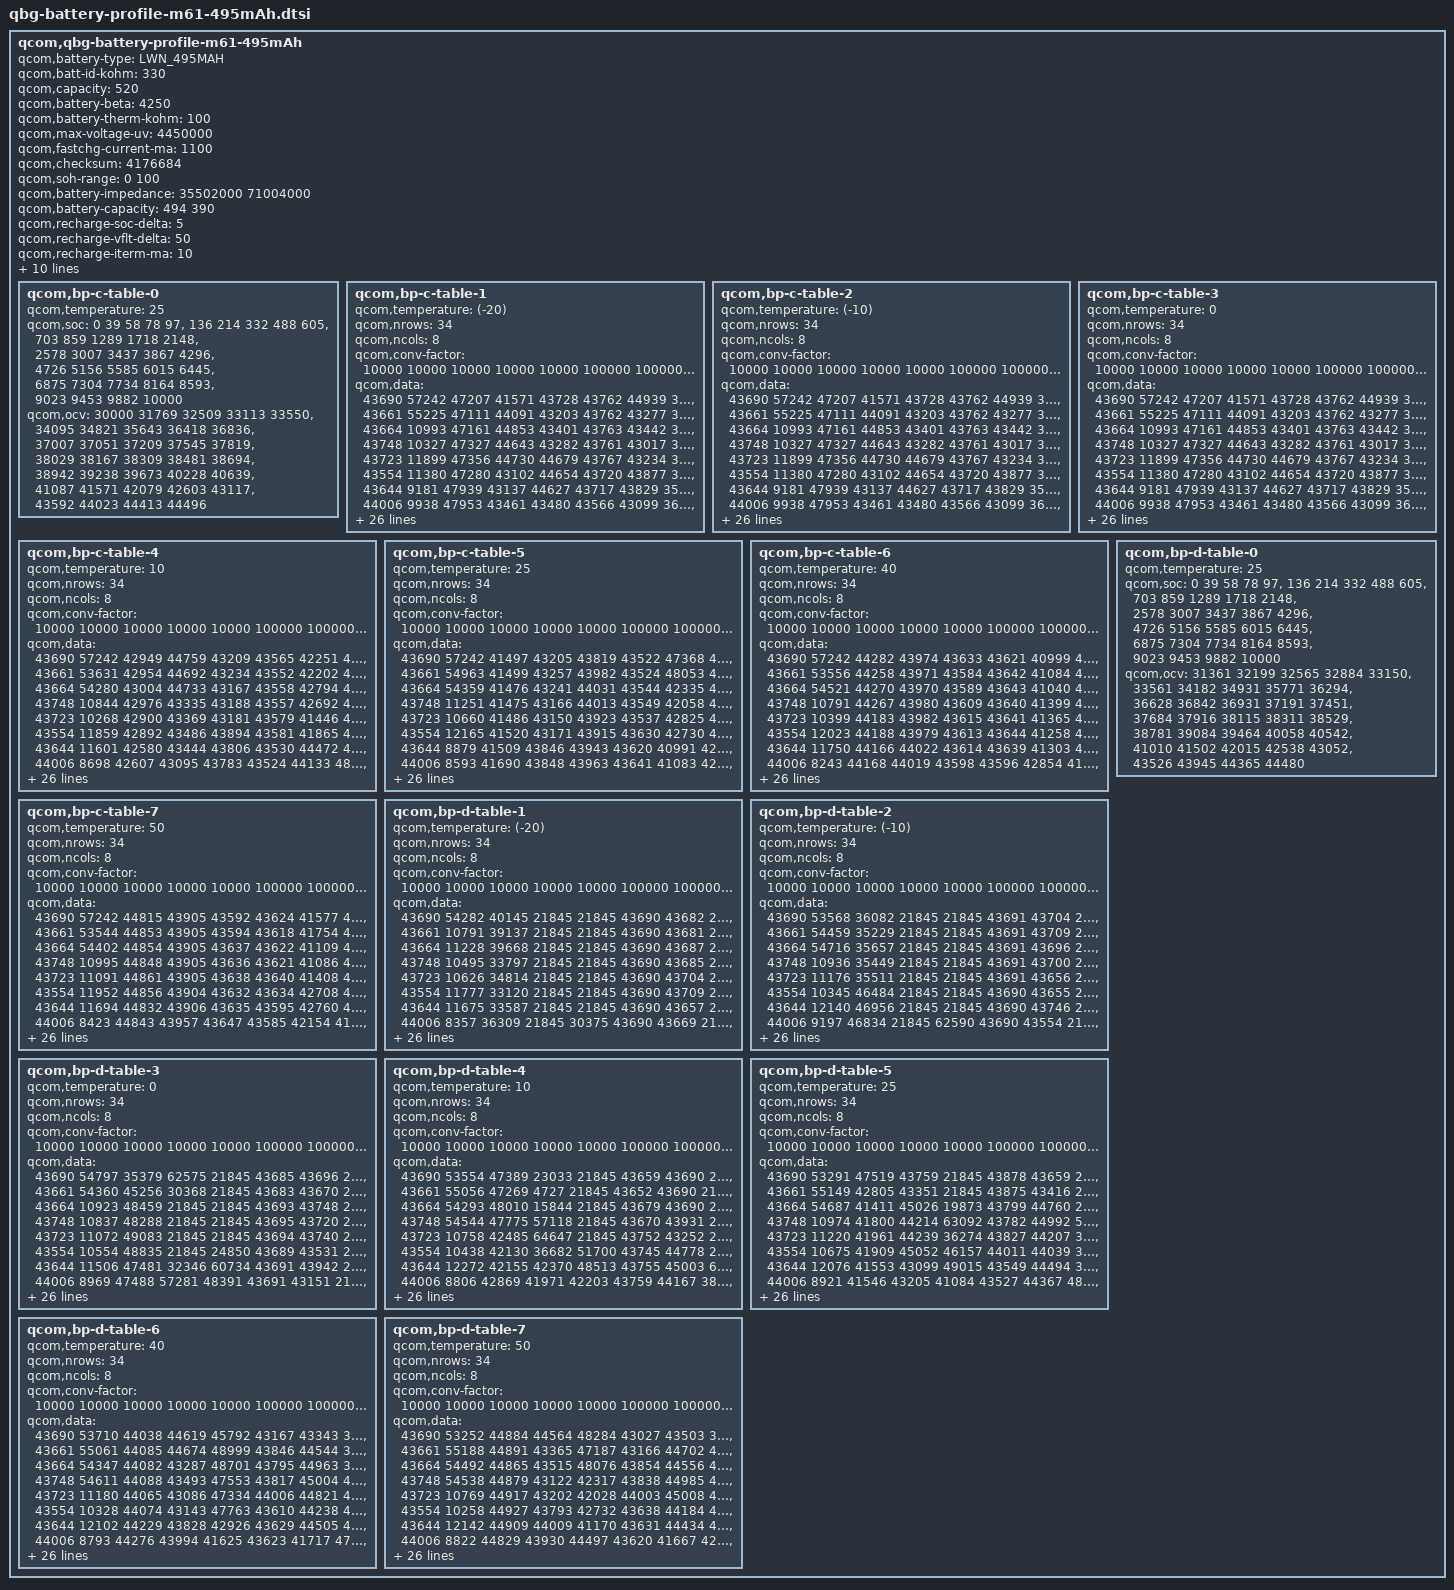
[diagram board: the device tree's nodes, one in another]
qcom,qbg-battery-profile-m61-495mAh {
	qcom,battery-type = "LWN_495MAH";
	qcom,batt-id-kohm = <330>;
	qcom,capacity = <520>;
	qcom,battery-beta = <4250>;
	qcom,battery-therm-kohm = <100>;
	qcom,max-voltage-uv = <4450000>;
	qcom,fastchg-current-ma = <1100>;
	qcom,checksum = <4176684>; /*@5, 0.005V, 4% */
	qcom,soh-range = <0 100>;
	/* Nominal_Impedance in 10nohm @ SOC 50% 25C* 0:fresh cell, 1: aged cell */
	qcom,battery-impedance = <35502000 71004000>;
	/* Nominal_Capacity in mAh. 0: fresh cell, 1:aged cell */
	qcom,battery-capacity = <494 390>; 
	/* SOC delta (in percent) dropped from EOC SOC to enable recharge */
	qcom,recharge-soc-delta =<5>; 
	/* vfloat delta (in mV) dropped from regular vfloat in recharge */
	qcom,recharge-vflt-delta =<50>;
	/* Termination current (in mA) in recharge */
	qcom,recharge-iterm-ma = <10>;

	qcom,jeita-fcc-ranges = <20 170 227500
				171 430 1100000
				431 450 227500>;

	qcom,jeita-fv-ranges = <20 170 4420000
				171 430 4420000
				431 450 4420000>;

	/* COOL = 17 DegC, WARM = 43.1 DegC */
	qcom,jeita-soft-thresholds = <0x263b 0x13a4>;
	/* COLD = 2 DegC, HOT = 45 DegC */
	qcom,jeita-hard-thresholds = <0x3117 0x1290>;
	/* COOL = 17.1 DegC, WARM = 43 DegC*/
	qcom,jeita-soft-hys-thresholds = <0x2627 0x1382>;
	qcom,step-jeita-hysteresis = <5 5>;
	qcom,jeita-soft-fcc-ua = <227500 227500>;
	qcom,jeita-soft-fv-uv = <4420000 4420000>;

	qcom,bp-c-table-0 {
		qcom,temperature = <25>;
		qcom,soc = <    0    39    58    78    97>,
			<  136   214   332   488   605>,
			<  703   859  1289  1718  2148>,
			< 2578  3007  3437  3867  4296>,
			< 4726  5156  5585  6015  6445>,
			< 6875  7304  7734  8164  8593>,
			< 9023  9453  9882 10000>;
		qcom,ocv = <30000 31769 32509 33113 33550>,
			<34095 34821 35643 36418 36836>,
			<37007 37051 37209 37545 37819>,
			<38029 38167 38309 38481 38694>,
			<38942 39238 39673 40228 40639>,
			<41087 41571 42079 42603 43117>,
			<43592 44023 44413 44496>;
	};
	qcom,bp-c-table-1 {
		qcom,temperature = <(-20)>;
		qcom,nrows = <34>;
		qcom,ncols = <8>;
		qcom,conv-factor = <10000 10000 10000 10000 10000 100000 100000 10000>;
		qcom,data = <43690 57242 47207 41571 43728 43762 44939 34481>,
			<43661 55225 47111 44091 43203 43762 43277 32881>,
			<43664 10993 47161 44853 43401 43763 43442 32924>,
			<43748 10327 47327 44643 43282 43761 43017 33595>,
			<43723 11899 47356 44730 44679 43767 43234 33370>,
			<43554 11380 47280 43102 44654 43720 43877 36195>,
			<43644  9181 47939 43137 44627 43717 43829 35988>,
			<44006  9938 47953 43461 43480 43566 43099 36841>,
			<43842  9720 47937 44695 43226 43570 44070 36566>,
			<43255 14852 47920 43982 44568 43569 44029 35228>,
			<43029 14917 48117 43105 43308 43571 43241 35209>,
			<43505 15295 47996 44597 43138 43528 41627 35315>,
			<44963 15186 47928 44999 43402 43533 41365 36550>,
			<44060 14833 48085 44817 43380 43523 42708 36592>,
			<41678 16069 48118 44877 44747 43527 42938 36560>,
			<41144 16278 48091 44165 44765 43520 42565 36585>,
			<41237 16181 48058 44224 44649 43523 42933 36590>,
			<42951 15537 48061 44080 44652 43522 42593 36528>,
			<42417 15378 47682 44056 44663 43532 41423 35190>,
			<47714 15826 47731 44045 45025 43535 41876 36525>,
			<47324 13036 47735 44080 44086 43535 41563 36776>,
			<48782 13302 47691 44032 44442 43532 41429 36829>,
			<49019 12684 47741 44148 45003 43522 42288 35082>,
			<48597 14234 47625 44227 43278 43529 41212 35808>,
			<45959 13424 48046 44089 43290 43531 41745 35632>,
			<45169  2610 47642 44060 43340 43572 41584 34959>,
			<46626  2260 47655 44429 43288 43543 41593 34857>,
			<46236  3806 47674 44542 43359 43537 41681 35219>,
			<46414  3288 47719 44494 44993 43575 44455 36819>,
			<35643   723 48073 44317 44402 43574 44859 32903>,
			<35221   194 47930 44419 41321 43535 43345 39568>,
			<36423  1765 47934 43070 42133 43211 44022 39804>,
			<35888  1835 41458 43557 47821 43911 43542 39079>,
			<36282  1811 41645 43767 47709 43750 43545 39804>;
	};
	qcom,bp-c-table-2 {
		qcom,temperature = <(-10)>;
		qcom,nrows = <34>;
		qcom,ncols = <8>;
		qcom,conv-factor = <10000 10000 10000 10000 10000 100000 100000 10000>;
		qcom,data = <43690 57242 47207 41571 43728 43762 44939 34481>,
			<43661 55225 47111 44091 43203 43762 43277 32881>,
			<43664 10993 47161 44853 43401 43763 43442 32924>,
			<43748 10327 47327 44643 43282 43761 43017 33595>,
			<43723 11899 47356 44730 44679 43767 43234 33370>,
			<43554 11380 47280 43102 44654 43720 43877 36195>,
			<43644  9181 47939 43137 44627 43717 43829 35988>,
			<44006  9938 47953 43461 43480 43566 43099 36841>,
			<43842  9720 47937 44695 43226 43570 44070 36566>,
			<43255 14852 47920 43982 44568 43569 44029 35228>,
			<43029 14917 48117 43105 43308 43571 43241 35209>,
			<43505 15295 47996 44597 43138 43528 41627 35315>,
			<44963 15186 47928 44999 43402 43533 41365 36550>,
			<44060 14833 48085 44817 43380 43523 42708 36592>,
			<41678 16069 48118 44877 44747 43527 42938 36560>,
			<41144 16278 48091 44165 44765 43520 42565 36585>,
			<41237 16181 48058 44224 44649 43523 42933 36590>,
			<42951 15537 48061 44080 44652 43522 42593 36528>,
			<42417 15378 47682 44056 44663 43532 41423 35190>,
			<47714 15826 47731 44045 45025 43535 41876 36525>,
			<47324 13036 47735 44080 44086 43535 41563 36776>,
			<48782 13302 47691 44032 44442 43532 41429 36829>,
			<49019 12684 47741 44148 45003 43522 42288 35082>,
			<48597 14234 47625 44227 43278 43529 41212 35808>,
			<45959 13424 48046 44089 43290 43531 41745 35632>,
			<45169  2610 47642 44060 43340 43572 41584 34959>,
			<46626  2260 47655 44429 43288 43543 41593 34857>,
			<46236  3806 47674 44542 43359 43537 41681 35219>,
			<46414  3288 47719 44494 44993 43575 44455 36819>,
			<35643   723 48073 44317 44402 43574 44859 32903>,
			<35221   194 47930 44419 41321 43535 43345 39568>,
			<36423  1765 47934 43070 42133 43211 44022 39804>,
			<35888  1835 41458 43557 47821 43911 43542 39079>,
			<36282  1811 41645 43767 47709 43750 43545 39804>;
	};
	qcom,bp-c-table-3 {
		qcom,temperature = <0>;
		qcom,nrows = <34>;
		qcom,ncols = <8>;
		qcom,conv-factor = <10000 10000 10000 10000 10000 100000 100000 10000>;
		qcom,data = <43690 57242 47207 41571 43728 43762 44939 34481>,
			<43661 55225 47111 44091 43203 43762 43277 32881>,
			<43664 10993 47161 44853 43401 43763 43442 32924>,
			<43748 10327 47327 44643 43282 43761 43017 33595>,
			<43723 11899 47356 44730 44679 43767 43234 33370>,
			<43554 11380 47280 43102 44654 43720 43877 36195>,
			<43644  9181 47939 43137 44627 43717 43829 35988>,
			<44006  9938 47953 43461 43480 43566 43099 36841>,
			<43842  9720 47937 44695 43226 43570 44070 36566>,
			<43255 14852 47920 43982 44568 43569 44029 35228>,
			<43029 14917 48117 43105 43308 43571 43241 35209>,
			<43505 15295 47996 44597 43138 43528 41627 35315>,
			<44963 15186 47928 44999 43402 43533 41365 36550>,
			<44060 14833 48085 44817 43380 43523 42708 36592>,
			<41678 16069 48118 44877 44747 43527 42938 36560>,
			<41144 16278 48091 44165 44765 43520 42565 36585>,
			<41237 16181 48058 44224 44649 43523 42933 36590>,
			<42951 15537 48061 44080 44652 43522 42593 36528>,
			<42417 15378 47682 44056 44663 43532 41423 35190>,
			<47714 15826 47731 44045 45025 43535 41876 36525>,
			<47324 13036 47735 44080 44086 43535 41563 36776>,
			<48782 13302 47691 44032 44442 43532 41429 36829>,
			<49019 12684 47741 44148 45003 43522 42288 35082>,
			<48597 14234 47625 44227 43278 43529 41212 35808>,
			<45959 13424 48046 44089 43290 43531 41745 35632>,
			<45169  2610 47642 44060 43340 43572 41584 34959>,
			<46626  2260 47655 44429 43288 43543 41593 34857>,
			<46236  3806 47674 44542 43359 43537 41681 35219>,
			<46414  3288 47719 44494 44993 43575 44455 36819>,
			<35643   723 48073 44317 44402 43574 44859 32903>,
			<35221   194 47930 44419 41321 43535 43345 39568>,
			<36423  1765 47934 43070 42133 43211 44022 39804>,
			<35888  1835 41458 43557 47821 43911 43542 39079>,
			<36282  1811 41645 43767 47709 43750 43545 39804>;
	};
	qcom,bp-c-table-4 {
		qcom,temperature = <10>;
		qcom,nrows = <34>;
		qcom,ncols = <8>;
		qcom,conv-factor = <10000 10000 10000 10000 10000 100000 100000 10000>;
		qcom,data = <43690 57242 42949 44759 43209 43565 42251 45356>,
			<43661 53631 42954 44692 43234 43552 42202 45107>,
			<43664 54280 43004 44733 43167 43558 42794 45244>,
			<43748 10844 42976 43335 43188 43557 42692 45882>,
			<43723 10268 42900 43369 43181 43579 41446 45985>,
			<43554 11859 42892 43486 43894 43581 41865 45757>,
			<43644 11601 42580 43444 43806 43530 44472 48216>,
			<44006  8698 42607 43095 43783 43524 44133 48359>,
			<43842  9414 42498 43099 43784 43551 44496 49006>,
			<43255 15032 42496 43084 43837 43624 44402 49113>,
			<43029 14854 42554 43426 44003 43542 41055 49087>,
			<43505 14964 42697 43438 43814 43536 41557 49074>,
			<44963 15164 42654 43310 43226 43625 41045 48967>,
			<44060 14424 42649 43281 43438 43628 42531 48365>,
			<41678 16058 42624 43382 43487 43629 42924 48169>,
			<41144 15985 42686 44729 43270 43631 42828 48141>,
			<41237 16356 41292 44680 43281 43624 42997 48162>,
			<42951 16252 41236 44685 43302 43543 42668 48295>,
			<42417 15583 41230 44774 43322 43537 41249 48288>,
			<47714 15762 41222 44759 43267 43549 41168 48269>,
			<47324 12940 41228 44554 44709 43536 41667 48188>,
			<48782 13290 41249 44586 45054 43542 44500 48430>,
			<49019 12413 41433 44724 44809 43537 41657 48630>,
			<48597 14210 41439 44707 43104 43539 41920 48883>,
			<45959 13420 41439 44726 43104 43539 41910 48884>,
			<45169  2607 41464 44698 43083 43549 41673 48674>,
			<46626  2249 41434 44768 43449 43538 44376 48730>,
			<46236  3828 41278 44764 43488 43539 44379 48936>,
			<46414  3265 41242 44607 43325 43539 44293 48286>,
			<35643   735 41337 44653 44768 43549 44121 48425>,
			<35221   243 42668 44628 44225 43549 44905 45084>,
			<36423  1709 42682 44589 41837 43541 44685 46136>,
			<35888  1831 41357 43209 41671 43629 43785 45462>,
			<36282  1897 43961 43566 42594 43935 43588 48938>;
	};
	qcom,bp-c-table-5 {
		qcom,temperature = <25>;
		qcom,nrows = <34>;
		qcom,ncols = <8>;
		qcom,conv-factor = <10000 10000 10000 10000 10000 100000 100000 10000>;
		qcom,data = <43690 57242 41497 43205 43819 43522 47368 42116>,
			<43661 54963 41499 43257 43982 43524 48053 42828>,
			<43664 54359 41476 43241 44031 43544 42335 42768>,
			<43748 11251 41475 43166 44013 43549 42058 42784>,
			<43723 10660 41486 43150 43923 43537 42825 42992>,
			<43554 12165 41520 43171 43915 43630 42730 42923>,
			<43644  8879 41509 43846 43943 43620 40991 42511>,
			<44006  8593 41690 43848 43963 43641 41083 42713>,
			<43842  9448 41720 43896 43961 43594 41189 42645>,
			<43255  9550 41721 43875 43936 43592 40972 42686>,
			<43029 14885 41620 43776 43613 43599 41074 41331>,
			<43505 14865 41630 43799 43966 43594 40961 41309>,
			<44963 15347 41653 43863 43901 43592 41853 42615>,
			<44060 14339 41636 43170 43185 43638 41045 42915>,
			<41678 14609 44382 43151 43215 43639 41325 42992>,
			<41144 15911 44361 43156 43224 43638 42681 42945>,
			<41237 16317 44388 43246 43261 43635 42496 42904>,
			<42951 16143 44318 43152 43161 43642 41092 42562>,
			<42417 15611 44297 43257 43154 43623 41930 42591>,
			<47714 15756 44347 43207 43257 43619 41646 42931>,
			<47324 12980 44330 43022 43065 43617 44540 42794>,
			<48782 13292 44504 43014 43397 43642 44182 42166>,
			<49019 12371 44495 43206 43431 43642 44267 42782>,
			<48597 14222 44529 43144 43799 43617 41615 41308>,
			<45959 13333 44541 43144 43781 43620 44307 41289>,
			<45169  2773 44538 43136 43884 43642 44428 41301>,
			<46626  2249 44537 43143 43865 43642 44229 42649>,
			<46236  3829 44533 43239 43146 43642 44060 42534>,
			<46414  3265 44481 43214 43249 43620 44079 42586>,
			<35643   711 44503 43220 43021 43642 44066 42944>,
			<35221   226 44336 43061 43413 43646 44246 42226>,
			<36423   349 44289 43067 44646 43643 44652 42364>,
			<35888  2007 44424 43840 44915 43621 43091 47782>,
			<36282  1914 43680 43926 41722 43999 43897 41494>;
	};
	qcom,bp-c-table-6 {
		qcom,temperature = <40>;
		qcom,nrows = <34>;
		qcom,ncols = <8>;
		qcom,conv-factor = <10000 10000 10000 10000 10000 100000 100000 10000>;
		qcom,data = <43690 57242 44282 43974 43633 43621 40999 41983>,
			<43661 53556 44258 43971 43584 43642 41084 41957>,
			<43664 54521 44270 43970 43589 43643 41040 41953>,
			<43748 10791 44267 43980 43609 43640 41399 41964>,
			<43723 10399 44183 43982 43615 43641 41365 41963>,
			<43554 12023 44188 43979 43613 43644 41258 41887>,
			<43644 11750 44166 44022 43614 43639 41303 41906>,
			<44006  8243 44168 44019 43598 43596 42854 41566>,
			<43842 10008 44222 44005 43639 43610 42874 41592>,
			<43255  9676 44219 44001 43633 43602 42191 41579>,
			<43029 15084 44196 43931 43537 43950 47640 41515>,
			<43505 14888 44204 43906 43644 43604 42700 41530>,
			<44963 15265 44200 44022 43995 43947 41096 41972>,
			<44060 14565 44883 44030 43820 43604 41022 41975>,
			<41678 14796 44890 44026 43788 43607 41763 41950>,
			<41144 16108 44878 44027 43789 43603 41932 41946>,
			<41237 15954 44914 44007 43989 43614 41123 41885>,
			<42951 16166 44897 43976 43988 43588 41924 41961>,
			<42417 15598 44821 43988 43835 43596 41519 41927>,
			<47714 15793 44829 43825 43805 43592 44345 41732>,
			<47324 12978 44804 43781 43847 43595 44256 41821>,
			<48782 13293 44813 43874 43188 43637 44223 41108>,
			<49019 12712 44810 43825 43892 43599 44066 41839>,
			<48597 14264 44849 43920 43934 43611 44497 41473>,
			<45959 13338 44861 44013 43918 43589 44372 41482>,
			<45169  2782 44850 44025 44010 43615 44488 41569>,
			<46626  2290 44848 43998 44021 43610 41611 41895>,
			<46236  3839 44855 43989 43815 43585 44304 41953>,
			<46414  3274 44808 43823 43881 43588 44449 41767>,
			<35643   753 44801 43825 43869 43591 44518 41800>,
			<35221   152 44818 43781 43140 43584 44511 41105>,
			<36423   369 44906 43777 43126 43586 44254 41024>,
			<35888  1987 45018 43831 43270 43612 44933 41469>,
			<36282  1892 43404 43644 41701 43926 43044 41281>;
	};
	qcom,bp-c-table-7 {
		qcom,temperature = <50>;
		qcom,nrows = <34>;
		qcom,ncols = <8>;
		qcom,conv-factor = <10000 10000 10000 10000 10000 100000 100000 10000>;
		qcom,data = <43690 57242 44815 43905 43592 43624 41577 41675>,
			<43661 53544 44853 43905 43594 43618 41754 41727>,
			<43664 54402 44854 43905 43637 43622 41109 41722>,
			<43748 10995 44848 43905 43636 43621 41086 41697>,
			<43723 11091 44861 43905 43638 43640 41408 41711>,
			<43554 11952 44856 43904 43632 43634 42708 41617>,
			<43644 11694 44832 43906 43635 43595 42760 41602>,
			<44006  8423 44843 43957 43647 43585 42154 41632>,
			<43842 10184 45008 43955 43645 43610 42030 44368>,
			<43255  9661 45022 43962 43620 43600 42097 44404>,
			<43029 15017 45016 43602 43525 43967 47896 44342>,
			<43505 15072 44997 43611 43539 43942 42580 44298>,
			<44963 14946 44998 43916 44028 43948 41052 41692>,
			<44060 14496 44995 43915 44030 43943 41331 41667>,
			<41678 14733 45000 43959 43982 43943 41206 41671>,
			<41144 16062 45040 43966 43976 43941 41737 41717>,
			<41237 15946 45048 43943 43925 43936 41186 41604>,
			<42951 16171 45026 43911 43927 43947 41003 41699>,
			<42417 15509 45032 43925 44016 43614 41544 41682>,
			<47714 15798 44950 44031 43986 43588 44388 41477>,
			<47324 12980 44957 43996 43835 43584 44420 41538>,
			<48782 13309 44955 43997 43804 43597 44278 41891>,
			<49019 12733 44935 43920 43819 43615 44070 41531>,
			<48597 14259 44930 43603 43945 43939 41700 44398>,
			<45959 13330 44937 43937 43600 43945 41880 44393>,
			<45169  2773 44942 43959 43964 43607 41568 44382>,
			<46626  2253 44943 43917 44011 43602 41682 41600>,
			<46236  3790 44940 44014 43978 43613 41888 41666>,
			<46414  3265 44930 44005 43823 43613 41527 41525>,
			<35643   718 44932 44028 43781 43612 41653 41599>,
			<35221   158 44957 43980 43901 43602 41631 41912>,
			<36423   381 44946 43973 43239 43606 44356 41788>,
			<35888  1985 44633 43909 43022 43943 44847 41920>,
			<36282  1913 43680 43574 41530 43940 43813 44570>;
	};
	qcom,bp-d-table-0 {
		qcom,temperature = <25>;
		qcom,soc = <    0    39    58    78    97>,
			<  136   214   332   488   605>,
			<  703   859  1289  1718  2148>,
			< 2578  3007  3437  3867  4296>,
			< 4726  5156  5585  6015  6445>,
			< 6875  7304  7734  8164  8593>,
			< 9023  9453  9882 10000>;
		qcom,ocv = <31361 32199 32565 32884 33150>,
			<33561 34182 34931 35771 36294>,
			<36628 36842 36931 37191 37451>,
			<37684 37916 38115 38311 38529>,
			<38781 39084 39464 40058 40542>,
			<41010 41502 42015 42538 43052>,
			<43526 43945 44365 44480>;
	};
	qcom,bp-d-table-1 {
		qcom,temperature = <(-20)>;
		qcom,nrows = <34>;
		qcom,ncols = <8>;
		qcom,conv-factor = <10000 10000 10000 10000 10000 100000 100000 10000>;
		qcom,data = <43690 54282 40145 21845 21845 43690 43682 21845>,
			<43661 10791 39137 21845 21845 43690 43681 21845>,
			<43664 11228 39668 21845 21845 43690 43687 21845>,
			<43748 10495 33797 21845 21845 43690 43685 21845>,
			<43723 10626 34814 21845 21845 43690 43704 21845>,
			<43554 11777 33120 21845 21845 43690 43709 21845>,
			<43644 11675 33587 21845 21845 43690 43657 21845>,
			<44006  8357 36309 21845 30375 43690 43669 21845>,
			<43842  9776 36225 21845 50109 43690 43736 21845>,
			<43255 10103 36286 21845 60673 43690 43524 21845>,
			<43029  9253 36758 21845 37431 43690 43641 21845>,
			<43505  9701 36602 21845 33458 43690 43952 21845>,
			<44963 15054 35219 31702 47045 43691 43984 21845>,
			<44060 15244 34941 10134 48847 43691 43879 21845>,
			<41678 15218 35674 49203 47800 43688 43173 21845>,
			<41144 14394 35631 62601 42476 43688 43139 21845>,
			<41237 14743 35071 63648 42064 43688 43190 23630>,
			<42951 14666 35449 58363 42019 43688 43140 18089>,
			<42417 16090 35755 60037 42144 43688 43197 19196>,
			<47714 15957 35759 37508 42772 43688 43863 31818>,
			<47324 16189 35394 39507 42778 43688 43843 25780>,
			<48782 15609 35404 33061 42768 43688 43866 28128>,
			<49019 15839 35329 33570 42209 43688 43092 28554>,
			<48597 13261 35838 33552 49047 43688 45001 25445>,
			<45959 12701 35719 33383 45525 43688 44746 25759>,
			<45169 14285 35808 32964 34890 43689 44793 31793>,
			<46626 13604 35723 34349 33715 43689 43386 29855>,
			<46236  2849 35440 34176 33125 43689 43447 18745>,
			<46414  2338 35449 39310 34745 43689 43129 17320>,
			<35643  3847 35741 40280 34208 43694 43021 23533>,
			<35221  3399 35834 38493 39340 43694 43137 22222>,
			<36423   203 35615 58051 34004 43689 43879 21845>,
			<35888  1930 34969 64851 34912 43689 43820 21845>,
			<36282  1863 34966 63156 46139 43689 43986 21845>;
	};
	qcom,bp-d-table-2 {
		qcom,temperature = <(-10)>;
		qcom,nrows = <34>;
		qcom,ncols = <8>;
		qcom,conv-factor = <10000 10000 10000 10000 10000 100000 100000 10000>;
		qcom,data = <43690 53568 36082 21845 21845 43691 43704 21845>,
			<43661 54459 35229 21845 21845 43691 43709 21845>,
			<43664 54716 35657 21845 21845 43691 43696 21845>,
			<43748 10936 35449 21845 21845 43691 43700 21845>,
			<43723 11176 35511 21845 21845 43691 43656 21845>,
			<43554 10345 46484 21845 21845 43690 43655 21845>,
			<43644 12140 46956 21845 21845 43690 43746 21845>,
			<44006  9197 46834 21845 62590 43690 43554 21845>,
			<43842  9785 45538 21845 36347 43690 43946 21845>,
			<43255  9448 45268 18073 46792 43691 43874 21845>,
			<43029  9285 45123  6051 48217 43691 43850 21845>,
			<43505  9671 45161  9665 42356 43691 43172 21845>,
			<44963 14998 46037 52544 41337 43691 43212 24339>,
			<44060 15259 45983 63707 41219 43691 43071 29513>,
			<41678 14476 45942 37950 41300 43688 43112 27547>,
			<41144 14415 45928 33027 41468 43688 43106   752>,
			<41237 14638 46075 46327 40965 43689 43032 16268>,
			<42951 16034 45859 48971 41091 43689 43226 11308>,
			<42417 15918 46047 42352 41730 43694 43152 53354>,
			<47714 16292 46069 42685 41983 43695 43189 56038>,
			<47324 16223 46029 41277 41145 43683 43302 51108>,
			<48782 15813 45851 42891 42824 43700 44225 50426>,
			<49019 12877 45252 42554 47875 43749 45005 50258>,
			<48597 12304 46077 42963 49124 43553 45021 55531>,
			<45959 13904 46049 47857 45313 43582 44816 53432>,
			<45169 13723 46047 47313 35763 43578 44984 54637>,
			<46626  2956 45926 48693 35738 43560 44790 10390>,
			<46236  2470 45827 48381 46421 43736 44730 10504>,
			<46414  4028 46061 48390 46450 43715 44715 12052>,
			<35643  3481 45883 45990 35427 43726 44718  8982>,
			<35221   903 45865 45941 35349 43767 43481  9943>,
			<36423    88 46038 45209 46019 43757 43008  8417>,
			<35888  1950 45865 45294 42352 43651 43776 10684>,
			<36282  1858 45859 45202 42069 43656 43978 10943>;
	};
	qcom,bp-d-table-3 {
		qcom,temperature = <0>;
		qcom,nrows = <34>;
		qcom,ncols = <8>;
		qcom,conv-factor = <10000 10000 10000 10000 10000 100000 100000 10000>;
		qcom,data = <43690 54797 35379 62575 21845 43685 43696 21845>,
			<43661 54360 45256 30368 21845 43683 43670 21845>,
			<43664 10923 48459 21845 21845 43693 43748 21845>,
			<43748 10837 48288 21845 21845 43695 43720 21845>,
			<43723 11072 49083 21845 21845 43694 43740 21845>,
			<43554 10554 48835 21845 24850 43689 43531 21845>,
			<43644 11506 47481 32346 60734 43691 43942 21845>,
			<44006  8969 47488 57281 48391 43691 43151 21845>,
			<43842  9850 47193 40430 42604 43688 43117  1670>,
			<43255  9424 47117 36647 42509 43688 43037 15151>,
			<43029  9606 47132 45406 41244 43689 43014 10821>,
			<43505  9531 47159 47491 41969 43694 43008 50349>,
			<44963 15080 47263 41264 44503 43682 43424 64795>,
			<44060 15150 47284 44414 44470 43661 44628 58009>,
			<41678 14397 47342 44089 44338 43736 44452 38298>,
			<41144 14829 47244 44866 44041 43557 44465 40419>,
			<41237 14699 47252 45008 45037 43573 44132 39718>,
			<42951 16096 47277 45043 44639 43531 44477 33941>,
			<42417 16313 47295 45017 44263 43532 44444 33935>,
			<47714 15531 47328 44827 44524 43523 44103 34678>,
			<47324 15776 47342 44202 44313 43523 44050 34774>,
			<48782 13026 47941 44282 41518 43521 44063 34562>,
			<49019 13154 47294 44033 41130 43520 44274 33919>,
			<48597 12568 47269 44493 42763 43527 44219 39318>,
			<45959 13485 47988 41473 47423 43539 45003 37065>,
			<45169 13632 47992 41579 47178 43526 43359 37714>,
			<46626  2920 47893 41866 47665 43530 43293 37441>,
			<46236  2320 47995 41783 42476 43570 44730 37490>,
			<46414  3949 47954 41833 42394 43583 44755 37721>,
			<35643  3425 47963 41738 42314 43583 44591 38655>,
			<35221   774 47232 41942 42305 43580 44744 38778>,
			<36423   498 47326 41888 42549 43557 44786 38515>,
			<35888  2016 47201 41689 41705 43566 44742 37780>,
			<36282  1911 47224 41726 44403 43561 44753 40206>;
	};
	qcom,bp-d-table-4 {
		qcom,temperature = <10>;
		qcom,nrows = <34>;
		qcom,ncols = <8>;
		qcom,conv-factor = <10000 10000 10000 10000 10000 100000 100000 10000>;
		qcom,data = <43690 53554 47389 23033 21845 43659 43690 21845>,
			<43661 55056 47269  4727 21845 43652 43690 21845>,
			<43664 54293 48010 15844 21845 43679 43690 21845>,
			<43748 54544 47775 57118 21845 43670 43931 21845>,
			<43723 10758 42485 64647 21845 43752 43252 21845>,
			<43554 10438 42130 36682 51700 43745 44778 26294>,
			<43644 12272 42155 42370 48513 43755 45003 61447>,
			<44006  8806 42869 41971 42203 43759 44167 38264>,
			<43842  9865 42758 44073 41868 43769 44172 34187>,
			<43255  9396 42799 44913 44407 43742 44032 33620>,
			<43029  9626 42822 45040 44436 43740 44825 36275>,
			<43505  9569 42957 44753 44837 43736 44975 35016>,
			<44963 15074 42891 43378 43350 43555 44865 46879>,
			<44060 15308 42574 43503 43480 43572 45007 45294>,
			<41678 14529 42573 43394 43416 43547 44259 45624>,
			<41144 14747 42562 43511 43295 43550 41712 45603>,
			<41237 14661 42499 43509 44625 43626 44324 45964>,
			<42951 15874 42552 43322 44986 43631 44499 45651>,
			<42417 16322 42692 43275 44575 43630 44474 45750>,
			<47714 15599 42721 43276 44775 43624 44143 48577>,
			<47324 15846 42640 43281 44691 43627 44100 48537>,
			<48782 12843 42628 43367 44793 43541 44144 48565>,
			<49019 12456 42627 44711 45019 43543 44102 45775>,
			<48597 14005 42635 44648 41178 43624 44249 46266>,
			<45959 13470 42735 44671 41340 43626 44713 46444>,
			<45169  2748 42728 44614 41817 43549 43508 46257>,
			<46626  2900 42749 44938 44344 43526 43291 46840>,
			<46236  2388 42707 44958 44037 43522 44762 46754>,
			<46414  3234 42558 44981 44067 43522 44639 46846>,
			<35643   673 42616 44979 44158 43520 45017 47064>,
			<35221   835 42583 44639 44419 43525 44829 46136>,
			<36423   289 42920 44545 44071 43545 44902 46098>,
			<35888  2042 42582 44769 45033 43551 44829 46143>,
			<36282  1918 42578 44703 44617 43551 44809 46290>;
	};
	qcom,bp-d-table-5 {
		qcom,temperature = <25>;
		qcom,nrows = <34>;
		qcom,ncols = <8>;
		qcom,conv-factor = <10000 10000 10000 10000 10000 100000 100000 10000>;
		qcom,data = <43690 53291 47519 43759 21845 43878 43659 21845>,
			<43661 55149 42805 43351 21845 43875 43416 21845>,
			<43664 54687 41411 45026 19873 43799 44760 23945>,
			<43748 10974 41800 44214 63092 43782 44992 50578>,
			<43723 11220 41961 44239 36274 43827 44207 37859>,
			<43554 10675 41909 45052 46157 44011 44039 33799>,
			<43644 12076 41553 43099 49015 43549 44494 35130>,
			<44006  8921 41546 43205 41084 43527 44367 48403>,
			<43842  8465 41573 43163 44597 43624 41707 48041>,
			<43255 10092 41578 43151 43456 43631 41589 42274>,
			<43029  9662 41490 43144 43075 43622 41664 42075>,
			<43505  9536 41484 43146 43059 43645 44429 42046>,
			<44963 15081 41529 43850 43820 43634 41089 42915>,
			<44060 15341 41682 43872 43818 43636 41589 42514>,
			<41678 14561 41719 43885 43777 43594 41887 42512>,
			<41144 14750 41703 43842 43201 43599 41915 42962>,
			<41237 16054 41606 43181 43275 43595 44368 42037>,
			<42951 15945 41661 43183 43300 43595 44156 42194>,
			<42417 16141 41647 43168 43432 43636 44155 42864>,
			<47714 15403 44379 43183 43054 43635 44062 42899>,
			<47324 15831 44404 43842 43240 43644 44868 42598>,
			<48782 12806 44414 43864 43166 43621 44214 42512>,
			<49019 12418 44411 43138 43099 43640 44054 42756>,
			<48597 14032 44398 43108 41626 43639 44944 47413>,
			<45959 13556 44393 43109 44168 43643 43295 47927>,
			<45169  2712 44386 43021 44690 43625 43318 42272>,
			<46626  2228 44408 43043 43501 43540 44716 42022>,
			<46236  3765 44366 43203 43109 43626 44782 42838>,
			<46414  3200 44373 43153 43064 43624 44693 42776>,
			<35643   646 41661 43162 43224 43625 44670 42767>,
			<35221   172 41631 43137 43201 43616 44923 42858>,
			<36423   259 41675 43167 43216 43621 44417 42158>,
			<35888  2023 41534 43235 43060 43641 41698 42237>,
			<36282  1898 41483 43237 43014 43646 41615 42184>;
	};
	qcom,bp-d-table-6 {
		qcom,temperature = <40>;
		qcom,nrows = <34>;
		qcom,ncols = <8>;
		qcom,conv-factor = <10000 10000 10000 10000 10000 100000 100000 10000>;
		qcom,data = <43690 53710 44038 44619 45792 43167 43343 36825>,
			<43661 55061 44085 44674 48999 43846 44544 35711>,
			<43664 54347 44082 43287 48701 43795 44963 35514>,
			<43748 54611 44088 43493 47553 43817 45004 46320>,
			<43723 11180 44065 43086 47334 44006 44821 46611>,
			<43554 10328 44074 43143 47763 43610 44238 45927>,
			<43644 12102 44229 43828 42926 43629 44505 48996>,
			<44006  8793 44276 43994 41625 43623 41717 47642>,
			<43842  9891 44286 43981 43408 43638 41882 41273>,
			<43255 10078 44259 44019 43846 43593 41767 41092>,
			<43029  9600 44269 43980 43854 43584 41914 41101>,
			<43505  9586 44268 44016 43850 43588 44466 41138>,
			<44963 14989 44177 43919 43951 43602 41249 41552>,
			<44060 15256 44165 43905 44004 43951 41124 41874>,
			<41678 14493 44168 43911 43813 43605 41860 41946>,
			<41144 14780 44221 43953 43786 43951 44332 41935>,
			<41237 16007 44216 43927 43113 43967 44448 41015>,
			<42951 16298 44194 43933 43010 43942 44885 41171>,
			<42417 16149 44886 43909 43150 43945 44923 41800>,
			<47714 15420 44889 43907 43873 43605 44882 41949>,
			<47324 15675 44870 43917 43824 43600 44258 41952>,
			<48782 12817 44877 44014 43817 43613 44493 41952>,
			<49019 12440 44917 44003 43180 43610 44200 41854>,
			<48597 14032 44873 43889 44566 43595 44600 42886>,
			<45959 13549 44872 43877 43414 43647 44582 41216>,
			<45169  2746 44878 43788 43247 43646 44592 40992>,
			<46626  2909 44877 43827 43877 43646 44933 41133>,
			<46236  2399 44870 43833 43810 43645 44266 41750>,
			<46414  3927 44892 43985 43968 43595 44053 41766>,
			<35643  3412 44205 44021 43976 43586 44119 41944>,
			<35221   880 44217 44018 44022 43585 44377 41920>,
			<36423   296 44170 43926 43972 43608 44534 41932>,
			<35888  1949 44165 43967 43813 43600 44835 41929>,
			<36282  1819 44184 43942 43836 43606 44644 41928>;
	};
	qcom,bp-d-table-7 {
		qcom,temperature = <50>;
		qcom,nrows = <34>;
		qcom,ncols = <8>;
		qcom,conv-factor = <10000 10000 10000 10000 10000 100000 100000 10000>;
		qcom,data = <43690 53252 44884 44564 48284 43027 43503 35049>,
			<43661 55188 44891 43365 47187 43166 44702 46939>,
			<43664 54492 44865 43515 48076 43854 44556 45420>,
			<43748 54538 44879 43122 42317 43838 44985 45829>,
			<43723 10769 44917 43202 42028 44003 45008 48491>,
			<43554 10258 44927 43793 42732 43638 44184 48651>,
			<43644 12142 44909 44009 41170 43631 44434 47337>,
			<44006  8822 44829 43930 44497 43620 41667 42425>,
			<43842  8521 44802 43912 43097 43637 41910 41163>,
			<43255 10082 44802 43955 43800 43584 41746 41895>,
			<43029  9302 44812 43914 43900 43584 41645 41885>,
			<43505  9473 44808 43953 43845 43608 44139 41955>,
			<44963  9556 44852 43607 43950 43939 42167 41600>,
			<44060 15266 44863 43614 44002 43966 41820 41716>,
			<41678 14500 44838 43610 43998 43955 41708 41686>,
			<41144 14404 44844 43637 43997 43965 44097 41676>,
			<41237 16052 45013 43597 43162 43961 44870 41866>,
			<42951 16298 45008 43589 43151 43955 45028 41904>,
			<42417 16237 45018 43608 43902 43954 45011 41568>,
			<47714 15370 44994 43615 43811 43943 44235 41684>,
			<47324 15670 45006 43604 44022 43947 44518 41725>,
			<48782 12911 45003 43937 44001 43607 44302 41703>,
			<49019 12439 45047 43910 43835 43615 44530 41494>,
			<48597 14037 45040 43813 43460 43596 44979 41400>,
			<45959 13461 45001 43970 43211 43638 44561 41853>,
			<45169  2735 45002 43976 43776 43594 44803 41871>,
			<46626  2886 45046 44016 43978 43595 44123 41572>,
			<46236  2381 45002 44014 43924 43595 44293 41533>,
			<46414  3908 44993 43928 43909 43598 41618 41693>,
			<35643  3393 45019 43913 43907 43589 41544 41675>,
			<35221   878 45017 43943 43919 43613 41486 41709>,
			<36423   453 45008 43604 43911 43944 41683 41620>,
			<35888  1933 44841 43614 44010 43962 41715 41617>,
			<36282  1800 44847 43609 44015 43966 41721 41622>;
	};
};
